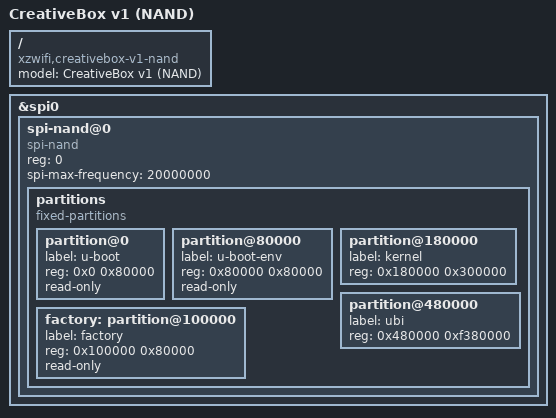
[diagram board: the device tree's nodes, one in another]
/dts-v1/;

#include "CreativeBox-v1.dtsi"

/ {
	compatible = "xzwifi,creativebox-v1-nand", "mediatek,mt7621-soc";
	model = "CreativeBox v1 (NAND)";
};

&spi0 {
	status = "okay";

	spi-nand@0 {
		compatible = "spi-nand";
		reg = <0>;
		spi-max-frequency = <20000000>;

		partitions {
			compatible = "fixed-partitions";
			#address-cells = <1>;
			#size-cells = <1>;

			partition@0 {
				label = "u-boot";
				reg = <0x0 0x80000>;
				read-only;
			};

			partition@80000 {
				label = "u-boot-env";
				reg = <0x80000 0x80000>;
				read-only;
			};

			factory: partition@100000 {
				label = "factory";
				reg = <0x100000 0x80000>;
				read-only;
			};

			partition@180000 {
				label = "kernel";
				reg = <0x180000 0x300000>;
			};

			partition@480000 {
				label = "ubi";
				reg = <0x480000 0xf380000>;
			};
		};
	};
};
